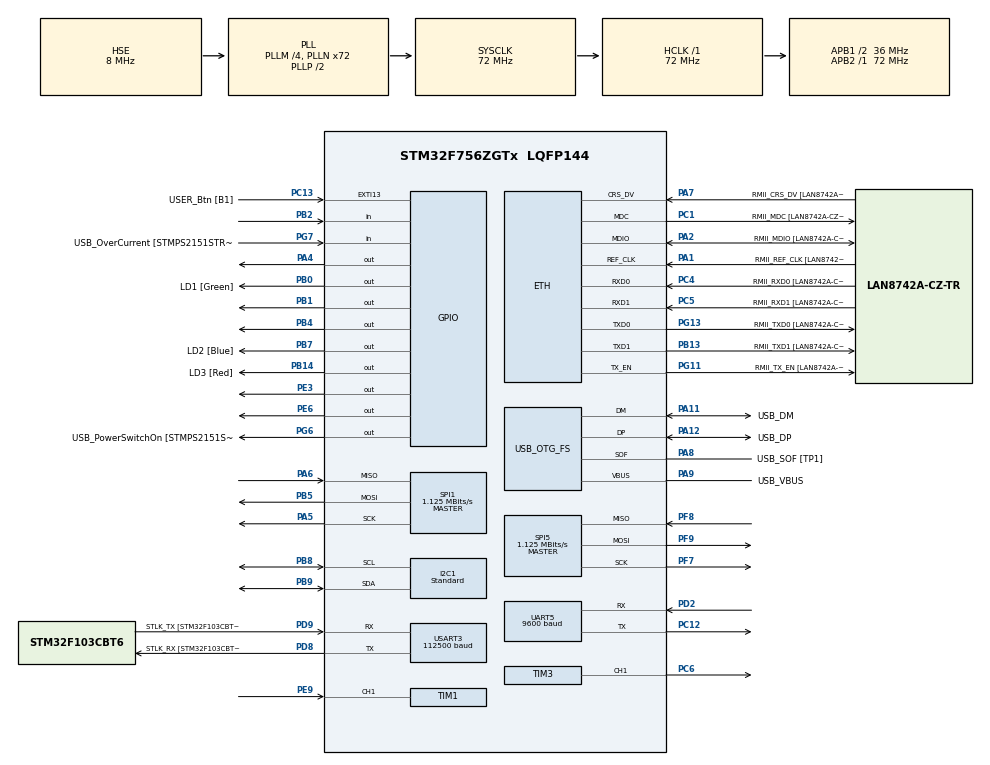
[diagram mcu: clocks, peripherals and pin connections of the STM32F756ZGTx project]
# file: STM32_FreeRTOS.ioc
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ETH.MediaInterface=HAL_ETH_RMII_MODE
ETH.PHY_Name=LAN8742A_PHY_ADDRESS
ETH.PHY_Value=0
ETH.PhyAddress=0
FREERTOS.Tasks01=TaskMainApp,8,128,main_application,As weak,NULL,Dynamic,NULL,NULL;TaskUltrasonic,40,128,Task_Ultrasonic_Handler,As weak,NULL,Dynamic,NULL,NULL;TaskOLED,24,128,Task_OLED_Handler,As weak,NULL,Dynamic,NULL,NULL;TaskLoRa,40,128,Task_LoRa_Handler,As weak,NULL,Dynamic,NULL,NULL;TaskServoMotor,24,128,Task_ServoMotor_Handler,As weak,NULL,Dynamic,NULL,NULL;TaskGPS,8,128,Task_GPS_Handler,As weak,NULL,Dynamic,NULL,NULL
I2C1.I2C_Speed_Mode=I2C_Standard
I2C1.Timing=0x00808CD2
Mcu.Family=STM32F7
Mcu.Name=STM32F756ZGTx
Mcu.Package=LQFP144
NVIC.I2C1_ER_IRQn=true\:5\:0\:false\:false\:true\:true\:true\:true\:true
NVIC.I2C1_EV_IRQn=true\:5\:0\:false\:false\:true\:true\:true\:true\:true
NVIC.PriorityGroup=NVIC_PRIORITYGROUP_4
NVIC.TIM1_CC_IRQn=true\:5\:0\:false\:false\:true\:true\:true\:true\:true
NVIC.UART5_IRQn=true\:5\:0\:false\:false\:true\:true\:true\:true\:true
PA1.GPIO_Label=RMII_REF_CLK [LAN8742A-CZ-TR_REFCLK0]
PA1.Mode=RMII
PA1.Signal=ETH_REF_CLK
PA10.GPIO_Label=USB_ID
PA10.Signal=USB_OTG_FS_ID
PA11.GPIO_Label=USB_DM
PA11.Mode=Device_Only
PA11.Signal=USB_OTG_FS_DM
PA12.GPIO_Label=USB_DP
PA12.Mode=Device_Only
PA12.Signal=USB_OTG_FS_DP
PA13.GPIO_Label=TMS
PA13.Mode=Serial_Wire
PA13.Signal=SYS_JTMS-SWDIO
PA14.GPIO_Label=TCK
PA14.Mode=Serial_Wire
PA14.Signal=SYS_JTCK-SWCLK
PA2.GPIO_Label=RMII_MDIO [LAN8742A-CZ-TR_MDIO]
PA2.Mode=RMII
PA2.Signal=ETH_MDIO
PA4.Signal=GPIO_Output
PA5.Mode=Full_Duplex_Master
PA5.Signal=SPI1_SCK
PA6.Mode=Full_Duplex_Master
PA6.Signal=SPI1_MISO
PA7.GPIO_Label=RMII_CRS_DV [LAN8742A-CZ-TR_CRS_DV]
PA7.Mode=RMII
PA7.Signal=ETH_CRS_DV
PA8.GPIO_Label=USB_SOF [TP1]
PA8.Mode=Activate_SOF_FS
PA8.Signal=USB_OTG_FS_SOF
PA9.GPIO_Label=USB_VBUS
PA9.Mode=Activate_VBUS
PA9.Signal=USB_OTG_FS_VBUS
PB0.GPIO_Label=LD1 [Green]
PB0.Signal=GPIO_Output
PB1.Signal=GPIO_Output
PB13.GPIO_Label=RMII_TXD1 [LAN8742A-CZ-TR_TXD1]
PB13.Mode=RMII
PB13.Signal=ETH_TXD1
PB14.GPIO_Label=LD3 [Red]
PB14.Signal=GPIO_Output
PB2.Signal=GPIO_Input
PB3.GPIO_Label=SW0
PB3.Signal=SYS_JTDO-SWO
PB4.Signal=GPIO_Output
PB5.Mode=Full_Duplex_Master
PB5.Signal=SPI1_MOSI
PB7.GPIO_Label=LD2 [Blue]
PB7.Signal=GPIO_Output
PB8.Mode=I2C
PB8.Signal=I2C1_SCL
PB9.Mode=I2C
PB9.Signal=I2C1_SDA
PC1.GPIO_Label=RMII_MDC [LAN8742A-CZ-TR_MDC]
PC1.Mode=RMII
PC1.Signal=ETH_MDC
PC12.Mode=Asynchronous
PC12.Signal=UART5_TX
PC13.GPIO_Label=USER_Btn [B1]
PC13.Signal=GPXTI13
PC14/OSC32_IN.Mode=LSE-External-Oscillator
PC14/OSC32_IN.Signal=RCC_OSC32_IN
PC15/OSC32_OUT.Mode=LSE-External-Oscillator
PC15/OSC32_OUT.Signal=RCC_OSC32_OUT
PC4.GPIO_Label=RMII_RXD0 [LAN8742A-CZ-TR_RXD0]
PC4.Mode=RMII
PC4.Signal=ETH_RXD0
PC5.GPIO_Label=RMII_RXD1 [LAN8742A-CZ-TR_RXD1]
PC5.Mode=RMII
PC5.Signal=ETH_RXD1
PC6.Signal=S_TIM3_CH1
PD2.GPIO_PuPd=GPIO_NOPULL
PD2.Mode=Asynchronous
PD2.Signal=UART5_RX
PD8.GPIO_Label=STLK_RX [STM32F103CBT6_PA3]
PD8.Mode=Asynchronous
PD8.Signal=USART3_TX
PD9.GPIO_Label=STLK_TX [STM32F103CBT6_PA2]
PD9.Mode=Asynchronous
PD9.Signal=USART3_RX
PE3.Signal=GPIO_Output
PE6.Signal=GPIO_Output
PE7.Signal=UART7_RX
PE9.Signal=S_TIM1_CH1
PF7.Mode=Full_Duplex_Master
PF7.Signal=SPI5_SCK
PF8.Mode=Full_Duplex_Master
PF8.Signal=SPI5_MISO
PF9.Mode=Full_Duplex_Master
PF9.Signal=SPI5_MOSI
PG11.GPIO_Label=RMII_TX_EN [LAN8742A-CZ-TR_TXEN]
PG11.Mode=RMII
PG11.Signal=ETH_TX_EN
PG13.GPIO_Label=RMII_TXD0 [LAN8742A-CZ-TR_TXD0]
PG13.Mode=RMII
PG13.Signal=ETH_TXD0
PG6.GPIO_Label=USB_PowerSwitchOn [STMPS2151STR_EN]
PG6.Signal=GPIO_Output
PG7.GPIO_Label=USB_OverCurrent [STMPS2151STR_FAULT]
PG7.Signal=GPIO_Input
PH0/OSC_IN.GPIO_Label=MCO [STM32F103CBT6_PA8]
PH0/OSC_IN.Mode=HSE-External-Clock-Source
PH0/OSC_IN.Signal=RCC_OSC_IN
PH1/OSC_OUT.Mode=HSE-External-Clock-Source
PH1/OSC_OUT.Signal=RCC_OSC_OUT
ProjectManager.HeapSize=0x200
ProjectManager.StackSize=0x400
ProjectManager.TargetToolchain=STM32CubeIDE
RCC.48MHZClocksFreq_Value=24000000
RCC.AHBFreq_Value=72000000
RCC.APB1CLKDivider=RCC_HCLK_DIV2
RCC.APB1Freq_Value=36000000
RCC.APB1TimFreq_Value=72000000
RCC.APB2Freq_Value=72000000
RCC.APB2TimFreq_Value=72000000
RCC.CortexFreq_Value=72000000
RCC.HCLKFreq_Value=72000000
RCC.HSE_VALUE=8000000
RCC.HSI_VALUE=16000000
RCC.PLLM=4
RCC.PLLMUL=RCC_PLL_MUL9
RCC.PLLN=72
RCC.PLLQ=3
RCC.PRESCALERUSB=RCC_USBCLKSOURCE_PLL_DIV1_5
RCC.SYSCLKFreq_VALUE=72000000
RCC.SYSCLKSource=RCC_SYSCLKSOURCE_PLLCLK
RCC.SYSCLKSourceVirtual=RCC_SYSCLKSOURCE_PLLCLK
RCC.USBFreq_Value=48000000
RCC.VCOOutputFreq_Value=144000000
SH.S_TIM1_CH1.0=TIM1_CH1,Input_Capture1_from_TI1
SH.S_TIM3_CH1.0=TIM3_CH1,PWM Generation1 CH1
SPI1.BaudRatePrescaler=SPI_BAUDRATEPRESCALER_64
SPI1.CalculateBaudRate=1.125 MBits/s
SPI1.DataSize=SPI_DATASIZE_8BIT
SPI1.Direction=SPI_DIRECTION_2LINES
SPI1.Mode=SPI_MODE_MASTER
SPI1.VirtualType=VM_MASTER
SPI5.BaudRatePrescaler=SPI_BAUDRATEPRESCALER_64
SPI5.CalculateBaudRate=1.125 MBits/s
SPI5.DataSize=SPI_DATASIZE_8BIT
SPI5.Direction=SPI_DIRECTION_2LINES
SPI5.Mode=SPI_MODE_MASTER
SPI5.VirtualType=VM_MASTER
TIM1.Channel-Input_Capture1_from_TI1=TIM_CHANNEL_1
TIM1.Period=65535-1
TIM1.Prescaler=72-1
TIM3.AutoReloadPreload=TIM_AUTORELOAD_PRELOAD_DISABLE
TIM3.Channel-PWM\ Generation1\ CH1=TIM_CHANNEL_1
TIM3.Period=19999
TIM3.Prescaler=71
TIM3.Pulse-PWM\ Generation1\ CH1=1500
UART5.BaudRate=9600
USART3.BaudRate=112500
USART3.VirtualMode-Asynchronous=VM_ASYNC
USB_OTG_FS.VirtualMode=Device_Only
VP_FREERTOS_VS_CMSIS_V2.Mode=CMSIS_V2
board=NUCLEO-F756ZG

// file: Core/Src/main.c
/* USER CODE BEGIN Header */
/**
  ******************************************************************************
  * @file           : main.c
  * @brief          : Main program body
  ******************************************************************************
  * @attention
  *
  * Copyright (c) 2025 STMicroelectronics.
  * All rights reserved.
  *
  * This software is licensed under terms that can be found in the LICENSE file
  * in the root directory of this software component.
  * If no LICENSE file comes with this software, it is provided AS-IS.
  *
  ******************************************************************************
  */
/* USER CODE END Header */
#include "main.h"
#include "cmsis_os.h"
#include "eth.h"
#include "i2c.h"
#include "spi.h"
#include "tim.h"
#include "usart.h"
#include "usb_otg.h"
#include "gpio.h"

void SystemClock_Config(void);
void MX_FREERTOS_Init(void);

int main(void)
{

  /* MCU Configuration--------------------------------------------------------*/

  /* Reset of all peripherals, Initializes the Flash interface and the Systick. */
  HAL_Init();

  /* Configure the system clock */
  SystemClock_Config();

  /* Initialize all configured peripherals */
  MX_GPIO_Init();
  MX_ETH_Init();
  MX_I2C1_Init();
  MX_USART3_UART_Init();
  MX_USB_OTG_FS_PCD_Init();
  MX_TIM1_Init();
  MX_SPI1_Init();
  MX_SPI5_Init();
  MX_TIM3_Init();
  MX_UART5_Init();

  /* Init scheduler */
  osKernelInitialize();

  /* Call init function for freertos objects (in cmsis_os2.c) */
  MX_FREERTOS_Init();

  /* Start scheduler */
  osKernelStart();

  /* We should never get here as control is now taken by the scheduler */

  /* Infinite loop */
  while (1)
  {

  }
}

void SystemClock_Config(void)
{
  RCC_OscInitTypeDef RCC_OscInitStruct = {0};
  RCC_ClkInitTypeDef RCC_ClkInitStruct = {0};

  /** Configure LSE Drive Capability
  */
  HAL_PWR_EnableBkUpAccess();

  /** Configure the main internal regulator output voltage
  */
  __HAL_RCC_PWR_CLK_ENABLE();
  __HAL_PWR_VOLTAGESCALING_CONFIG(PWR_REGULATOR_VOLTAGE_SCALE3);

  /** Initializes the RCC Oscillators according to the specified parameters
  * in the RCC_OscInitTypeDef structure.
  */
  RCC_OscInitStruct.OscillatorType = RCC_OSCILLATORTYPE_HSE;
  RCC_OscInitStruct.HSEState = RCC_HSE_BYPASS;
  RCC_OscInitStruct.PLL.PLLState = RCC_PLL_ON;
  RCC_OscInitStruct.PLL.PLLSource = RCC_PLLSOURCE_HSE;
  RCC_OscInitStruct.PLL.PLLM = 4;
  RCC_OscInitStruct.PLL.PLLN = 72;
  RCC_OscInitStruct.PLL.PLLP = RCC_PLLP_DIV2;
  RCC_OscInitStruct.PLL.PLLQ = 3;
  if (HAL_RCC_OscConfig(&RCC_OscInitStruct) != HAL_OK)
  {
    Error_Handler();
  }

  /** Initializes the CPU, AHB and APB buses clocks
  */
  RCC_ClkInitStruct.ClockType = RCC_CLOCKTYPE_HCLK|RCC_CLOCKTYPE_SYSCLK
                              |RCC_CLOCKTYPE_PCLK1|RCC_CLOCKTYPE_PCLK2;
  RCC_ClkInitStruct.SYSCLKSource = RCC_SYSCLKSOURCE_PLLCLK;
  RCC_ClkInitStruct.AHBCLKDivider = RCC_SYSCLK_DIV1;
  RCC_ClkInitStruct.APB1CLKDivider = RCC_HCLK_DIV2;
  RCC_ClkInitStruct.APB2CLKDivider = RCC_HCLK_DIV1;

  if (HAL_RCC_ClockConfig(&RCC_ClkInitStruct, FLASH_LATENCY_2) != HAL_OK)
  {
    Error_Handler();
  }
}

void Error_Handler(void)
{
  __disable_irq();
  while (1)
  {
  }
}

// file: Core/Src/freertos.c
/* USER CODE BEGIN Header */
/* USER CODE END Header */

#include "FreeRTOS.h"
#include "task.h"
#include "main.h"
#include "cmsis_os.h"

/* USER CODE BEGIN Includes */
#include "queue.h"
/* USER CODE END Includes */

/* USER CODE BEGIN Variables */
QueueHandle_t distanceQueue;  // Declare the queue handle
/* USER CODE END Variables */
/* Definitions for TaskMainApp */
osThreadId_t TaskMainAppHandle;
const osThreadAttr_t TaskMainApp_attributes = {
  .name = "TaskMainApp",
  .stack_size = 128 * 4,
  .priority = (osPriority_t) osPriorityLow,
};
/* Definitions for TaskUltrasonic */
osThreadId_t TaskUltrasonicHandle;
const osThreadAttr_t TaskUltrasonic_attributes = {
  .name = "TaskUltrasonic",
  .stack_size = 128 * 4,
  .priority = (osPriority_t) osPriorityHigh,
};
/* Definitions for TaskOLED */
osThreadId_t TaskOLEDHandle;
const osThreadAttr_t TaskOLED_attributes = {
  .name = "TaskOLED",
  .stack_size = 128 * 4,
  .priority = (osPriority_t) osPriorityNormal,
};
/* Definitions for TaskLoRa */
osThreadId_t TaskLoRaHandle;
const osThreadAttr_t TaskLoRa_attributes = {
  .name = "TaskLoRa",
  .stack_size = 128 * 4,
  .priority = (osPriority_t) osPriorityHigh,
};
/* Definitions for TaskServoMotor */
osThreadId_t TaskServoMotorHandle;
const osThreadAttr_t TaskServoMotor_attributes = {
  .name = "TaskServoMotor",
  .stack_size = 128 * 4,
  .priority = (osPriority_t) osPriorityNormal,
};
/* Definitions for TaskGPS */
osThreadId_t TaskGPSHandle;
const osThreadAttr_t TaskGPS_attributes = {
  .name = "TaskGPS",
  .stack_size = 128 * 4,
  .priority = (osPriority_t) osPriorityLow,
};

void main_application(void *argument);
void Task_Ultrasonic_Handler(void *argument);
void Task_OLED_Handler(void *argument);
void Task_LoRa_Handler(void *argument);
void Task_ServoMotor_Handler(void *argument);
void Task_GPS_Handler(void *argument);

void MX_FREERTOS_Init(void); /* (MISRA C 2004 rule 8.1) */

void MX_FREERTOS_Init(void) {

  /* USER CODE BEGIN RTOS_QUEUES */
  // Create the queue with space for 5 uint32_t values

  distanceQueue = xQueueCreate(10, sizeof(uint32_t));
  if (distanceQueue == NULL) {
      printf("\r Queue creation failed!\n");
  } else {
      printf("\r Queue created successfully.\n");
  }

  /* USER CODE END RTOS_QUEUES */

  /* Create the thread(s) */
  /* creation of TaskMainApp */
//  TaskMainAppHandle = osThreadNew(main_application, NULL, &TaskMainApp_attributes);
//
//  /* creation of TaskUltrasonic */
//  TaskUltrasonicHandle = osThreadNew(Task_Ultrasonic_Handler, NULL, &TaskUltrasonic_attributes);
//
//  /* creation of TaskOLED */
//  TaskOLEDHandle = osThreadNew(Task_OLED_Handler, NULL, &TaskOLED_attributes);
//
//  /* creation of TaskLoRa */
//  TaskLoRaHandle = osThreadNew(Task_LoRa_Handler, NULL, &TaskLoRa_attributes);
//
//  /* creation of TaskServoMotor */
//  TaskServoMotorHandle = osThreadNew(Task_ServoMotor_Handler, NULL, &TaskServoMotor_attributes);

  /* creation of TaskGPS */
  TaskGPSHandle = osThreadNew(Task_GPS_Handler, NULL, &TaskGPS_attributes);

}

__weak void main_application(void *argument)
{
}

__weak void Task_Ultrasonic_Handler(void *argument)
{
}

__weak void Task_OLED_Handler(void *argument)
{
}

__weak void Task_LoRa_Handler(void *argument)
{
  for(;;)
  {
    osDelay(1);
  }
}

__weak void Task_ServoMotor_Handler(void *argument)
{
  for(;;)
  {
    osDelay(1);
  }
}

__weak void Task_GPS_Handler(void *argument)
{
  for(;;)
  {
    osDelay(1);
  }
}
